VERSION "CAN-LoRa telemetry, protocol version 1"

NS_ :

BS_:

BU_: NODE0_ENV NODE1_PWR NODE2_MOT HUB

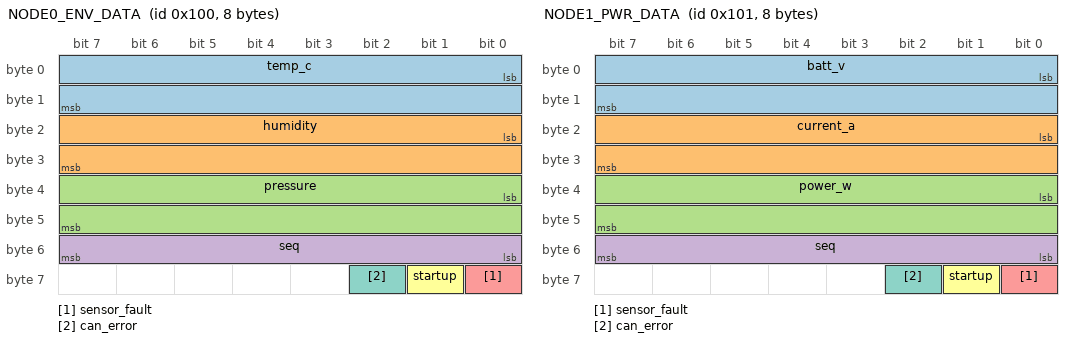
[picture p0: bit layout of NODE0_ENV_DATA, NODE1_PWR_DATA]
BO_ 256 NODE0_ENV_DATA: 8 NODE0_ENV
 SG_ temp_c : 0|16@1- (0.01,0) [-327.68|327.67] "degC" HUB
 SG_ humidity : 16|16@1- (0.01,0) [-327.68|327.67] "%RH" HUB
 SG_ pressure : 32|16@1- (0.1,0) [-3276.8|3276.7] "kPa" HUB
 SG_ seq : 48|8@1+ (1,0) [0|255] "" HUB
 SG_ sensor_fault : 56|1@1+ (1,0) [0|1] "" HUB
 SG_ startup : 57|1@1+ (1,0) [0|1] "" HUB
 SG_ can_error : 58|1@1+ (1,0) [0|1] "" HUB

BO_ 257 NODE1_PWR_DATA: 8 NODE1_PWR
 SG_ batt_v : 0|16@1- (0.001,0) [-32.768|32.767] "V" HUB
 SG_ current_a : 16|16@1- (0.001,0) [-32.768|32.767] "A" HUB
 SG_ power_w : 32|16@1- (0.1,0) [-3276.8|3276.7] "W" HUB
 SG_ seq : 48|8@1+ (1,0) [0|255] "" HUB
 SG_ sensor_fault : 56|1@1+ (1,0) [0|1] "" HUB
 SG_ startup : 57|1@1+ (1,0) [0|1] "" HUB
 SG_ can_error : 58|1@1+ (1,0) [0|1] "" HUB

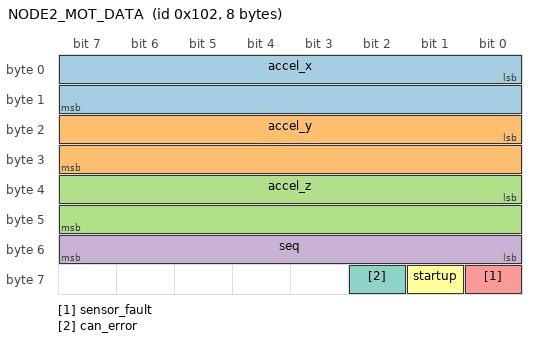
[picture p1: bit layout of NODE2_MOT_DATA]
BO_ 258 NODE2_MOT_DATA: 8 NODE2_MOT
 SG_ accel_x : 0|16@1- (0.001,0) [-32.768|32.767] "g" HUB
 SG_ accel_y : 16|16@1- (0.001,0) [-32.768|32.767] "g" HUB
 SG_ accel_z : 32|16@1- (0.001,0) [-32.768|32.767] "g" HUB
 SG_ seq : 48|8@1+ (1,0) [0|255] "" HUB
 SG_ sensor_fault : 56|1@1+ (1,0) [0|1] "" HUB
 SG_ startup : 57|1@1+ (1,0) [0|1] "" HUB
 SG_ can_error : 58|1@1+ (1,0) [0|1] "" HUB

CM_ "Generated by tools/gen_dbc.py on 2026-08-14. Do not edit by hand - edit TLM_CHANNELS in protocol/telemetry_proto.c and regenerate.";
CM_ BU_ NODE0_ENV "STM32F103C8 Bluepill, environmental node";
CM_ BO_ 256 "Environmental readings, sent every 100 ms";
CM_ SG_ 256 seq "Rolling counter, +1 per transmission. The hub uses gaps in this to measure frame loss.";
CM_ SG_ 256 sensor_fault "Node could not read a sensor";
CM_ SG_ 256 startup "Within the first two seconds after reset";
CM_ SG_ 256 can_error "Node saw bus errors or recovered from bus-off";
CM_ BU_ NODE1_PWR "STM32F103C8 Bluepill, power node";
CM_ BO_ 257 "Power readings, sent every 100 ms";
CM_ SG_ 257 seq "Rolling counter, +1 per transmission. The hub uses gaps in this to measure frame loss.";
CM_ SG_ 257 sensor_fault "Node could not read a sensor";
CM_ SG_ 257 startup "Within the first two seconds after reset";
CM_ SG_ 257 can_error "Node saw bus errors or recovered from bus-off";
CM_ BU_ NODE2_MOT "STM32F103C8 Bluepill, motion node";
CM_ BO_ 258 "Motion readings, sent every 100 ms";
CM_ SG_ 258 seq "Rolling counter, +1 per transmission. The hub uses gaps in this to measure frame loss.";
CM_ SG_ 258 sensor_fault "Node could not read a sensor";
CM_ SG_ 258 startup "Within the first two seconds after reset";
CM_ SG_ 258 can_error "Node saw bus errors or recovered from bus-off";
CM_ BU_ HUB "STM32L476RG, aggregates the bus and uplinks snapshots over LoRa";

BA_DEF_ BO_  "GenMsgCycleTime" INT 0 65535;
BA_DEF_ "BusType" STRING ;
BA_DEF_DEF_  "GenMsgCycleTime" 0;
BA_DEF_DEF_  "BusType" "CAN";
BA_ "GenMsgCycleTime" BO_ 256 100;
BA_ "GenMsgCycleTime" BO_ 257 100;
BA_ "GenMsgCycleTime" BO_ 258 100;

VAL_ 256 sensor_fault 1 "yes" 0 "no";
VAL_ 256 startup 1 "yes" 0 "no";
VAL_ 256 can_error 1 "yes" 0 "no";
VAL_ 257 sensor_fault 1 "yes" 0 "no";
VAL_ 257 startup 1 "yes" 0 "no";
VAL_ 257 can_error 1 "yes" 0 "no";
VAL_ 258 sensor_fault 1 "yes" 0 "no";
VAL_ 258 startup 1 "yes" 0 "no";
VAL_ 258 can_error 1 "yes" 0 "no";
